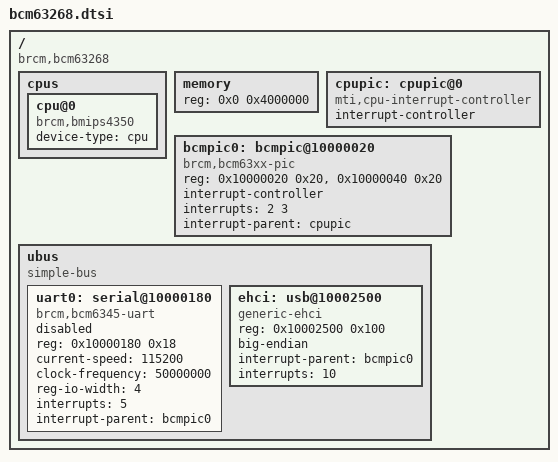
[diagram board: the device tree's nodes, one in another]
/ {
	#address-cells = <1>;
	#size-cells = <1>;
	compatible = "brcm,bcm63268";
	cpus {
		cpu@0 {
			device-type = "cpu";
			compatible = "brcm,bmips4350";
		};
	};
	memory {
		device_type = "memory";
		reg = <0x0 0x4000000>;
	};
	cpupic: cpupic@0 {
		#address-cells = <0>;
		#interrupt-cells = <1>;
		interrupt-controller;
		compatible = "mti,cpu-interrupt-controller";
	};
	bcmpic0: bcmpic@10000020 {
		#interrupt-cells = <1>;
		reg = <0x10000020 0x20>,
			<0x10000040 0x20>;
		interrupt-controller;
		interrupts = <2 3>;
		interrupt-parent = <&cpupic>;
		compatible = "brcm,bcm63xx-pic";
	};
	ubus {
		#address-cells = <1>;
		#size-cells = <1>;
		#interrupt-cells = <1>;
		compatible = "simple-bus";
		ranges = <0x10000000 0x10ffffff>;
		uart0: serial@10000180 {
			compatible = "brcm,bcm6345-uart";
			reg = <0x10000180 0x18>;
			current-speed = <115200>;
			clock-frequency = <50000000>;
			reg-io-width = <4>;
			interrupts = <5>;
			interrupt-parent = <&bcmpic0>;
			status = "disabled";
		};
		ehci: usb@10002500 {
			compatible = "generic-ehci";
			reg = <0x10002500 0x100>;
			big-endian;
			interrupt-parent = <&bcmpic0>;
			interrupts = <10>;
		};
/*		ohci: usb@10002600 { 
			compatible = "generic-ohci";
			reg = <0x10002600 0x100>;
			big-endian;
			interrupts = <41>;
			interrupt-parent = <&bcmpic0>;
			phys = <&usbphy 0>;
			phy-names = "usb";
		};*/
	};
};
